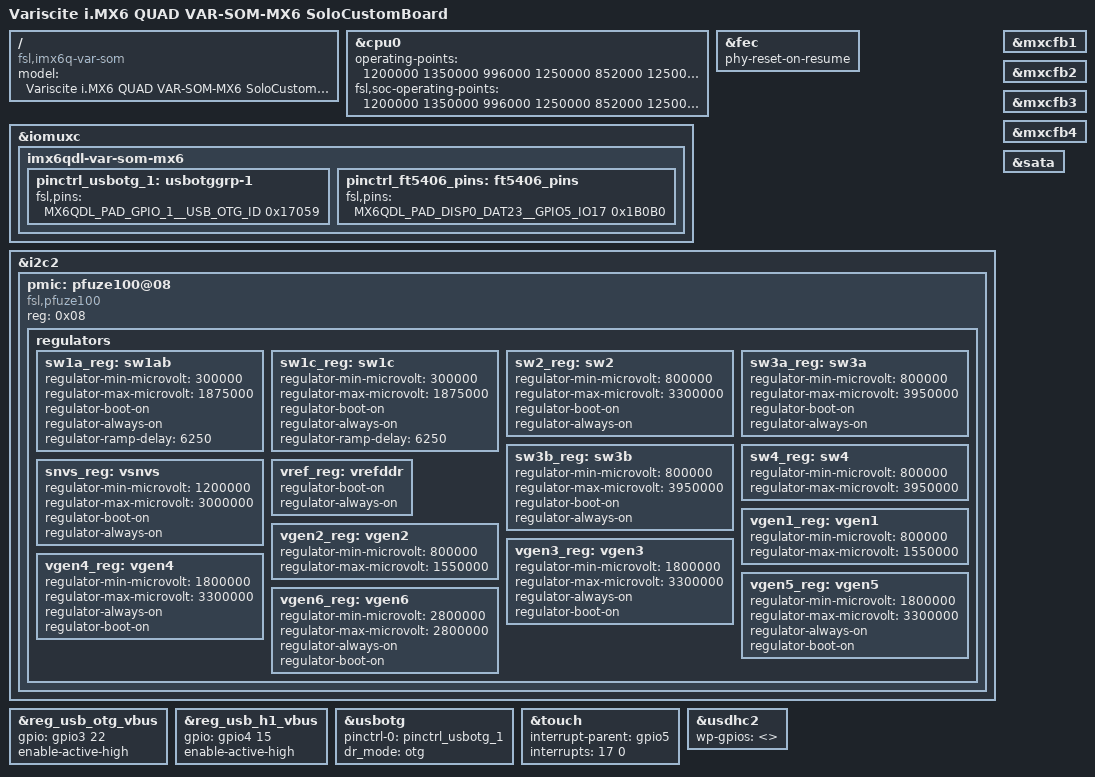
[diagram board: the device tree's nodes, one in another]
/*
 * Copyright (C) 2014-2016 Variscite, Ltd. All Rights Reserved
 * Donio Ron: ron.d@variscite.com
 *
 * Copyright 2012 Freescale Semiconductor, Inc.
 * Copyright 2011 Linaro Ltd.
 *
 * The code contained herein is licensed under the GNU General Public
 * License. You may obtain a copy of the GNU General Public License
 * Version 2 or later at the following locations:
 *
 * http://www.opensource.org/licenses/gpl-license.html
 * http://www.gnu.org/copyleft/gpl.html
 */

/dts-v1/;

#include "imx6q.dtsi"
#include "imx6qdl-var-som.dtsi"
#include "imx6qdl-var-solocb-dt6cb-displays.dtsi"
#include "imx6qdl-var-solocb-buttons.dtsi"

/ {
	model = "Variscite i.MX6 QUAD VAR-SOM-MX6 SoloCustomBoard";
	compatible = "fsl,imx6q-var-som", "fsl,imx6q";
};

&cpu0 {
	operating-points = <
		/* kHz    uV */
		1200000	1350000
		996000	1250000
		852000	1250000
		792000	1175000
		396000	1175000
	>;
	fsl,soc-operating-points = <
		/* ARM kHz  SOC-PU uV */
		1200000	1350000
		996000	1250000
		852000	1250000
		792000	1175000
		396000	1175000
	>;
};

&fec {
	phy-reset-on-resume;
};

&iomuxc {
	imx6qdl-var-som-mx6 {
		pinctrl_usbotg_1: usbotggrp-1 {
			fsl,pins = <
				MX6QDL_PAD_GPIO_1__USB_OTG_ID		0x17059
			>;
		};

		pinctrl_ft5406_pins: ft5406_pins {
			fsl,pins = <
				MX6QDL_PAD_DISP0_DAT23__GPIO5_IO17	0x1B0B0
			>;
		};
	};
};

&i2c2 {
	pmic: pfuze100@08 {
		compatible = "fsl,pfuze100";
		reg = <0x08>;
		regulators {
			sw1a_reg: sw1ab {
				regulator-min-microvolt = <300000>;
				regulator-max-microvolt = <1875000>;
				regulator-boot-on;
				regulator-always-on;
				regulator-ramp-delay = <6250>;
			};

			sw1c_reg: sw1c {
				regulator-min-microvolt = <300000>;
				regulator-max-microvolt = <1875000>;
				regulator-boot-on;
				regulator-always-on;
				regulator-ramp-delay = <6250>;
			};

			sw2_reg: sw2 {
				regulator-min-microvolt = <800000>;
				regulator-max-microvolt = <3300000>;
				regulator-boot-on;
				regulator-always-on;
			};

			sw3a_reg: sw3a {
				regulator-min-microvolt = <800000>;
				regulator-max-microvolt = <3950000>;
				regulator-boot-on;
				regulator-always-on;
			};

			sw3b_reg: sw3b {
				regulator-min-microvolt = <800000>;
				regulator-max-microvolt = <3950000>;
				regulator-boot-on;
				regulator-always-on;
			};

			sw4_reg: sw4 {
				regulator-min-microvolt = <800000>;
				regulator-max-microvolt = <3950000>;
			};

			snvs_reg: vsnvs {
				regulator-min-microvolt = <1200000>;
				regulator-max-microvolt = <3000000>;
				regulator-boot-on;
				regulator-always-on;
			};

			vref_reg: vrefddr {
				regulator-boot-on;
				regulator-always-on;
			};

			vgen1_reg: vgen1 {
				regulator-min-microvolt = <800000>;
				regulator-max-microvolt = <1550000>;
			};

			vgen2_reg: vgen2 {
				regulator-min-microvolt = <800000>;
				regulator-max-microvolt = <1550000>;
			};

			vgen3_reg: vgen3 {
				regulator-min-microvolt = <1800000>;
				regulator-max-microvolt = <3300000>;
				regulator-always-on;
				regulator-boot-on;
			};

			vgen4_reg: vgen4 {
				regulator-min-microvolt = <1800000>;
				regulator-max-microvolt = <3300000>;
				regulator-always-on;
				regulator-boot-on;
			};

			vgen5_reg: vgen5 {
				regulator-min-microvolt = <1800000>;
				regulator-max-microvolt = <3300000>;
				regulator-always-on;
				regulator-boot-on;
			};

			vgen6_reg: vgen6 {
				regulator-min-microvolt = <2800000>;
				regulator-max-microvolt = <2800000>;
				regulator-always-on;
				regulator-boot-on;
			};
		};
	};
};

&reg_usb_otg_vbus {
	gpio = <&gpio3 22 0>;
	enable-active-high;
};

&reg_usb_h1_vbus {
	gpio = <&gpio4 15 0>;
	enable-active-high;
};

&usbotg {
	pinctrl-0 = <&pinctrl_usbotg_1>;
	dr_mode = "otg"; /* Use "host" if you would like to use the USB0 type A connector */
};

&touch {
	interrupt-parent = <&gpio5>;
	interrupts = <17 0>;
};

&usdhc2 {	/* uSDHC2, MMC/SD card */
	wp-gpios = <>;
};

&mxcfb1 {
	status = "okay";
};

&mxcfb2 {
	status = "okay";
};

&mxcfb3 {
	status = "okay";
};

&mxcfb4 {
	status = "okay";
};

&sata {
	status = "okay";
};
